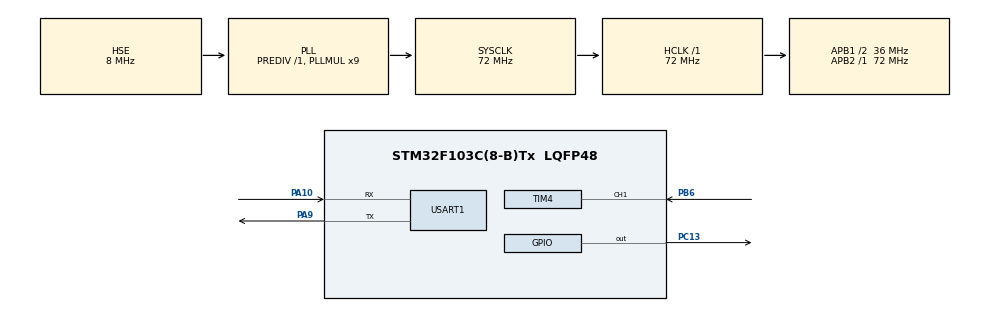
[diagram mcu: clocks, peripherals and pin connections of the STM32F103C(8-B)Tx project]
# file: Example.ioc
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FREERTOS.Tasks01=logger,0,512,StartLogger,Default,NULL,Dynamic,NULL,NULL
FREERTOS.configMAX_PRIORITIES=5
FREERTOS.configTOTAL_HEAP_SIZE=8192
Mcu.Family=STM32F1
Mcu.Name=STM32F103C(8-B)Tx
Mcu.Package=LQFP48
NVIC.PriorityGroup=NVIC_PRIORITYGROUP_4
NVIC.TIM2_IRQn=true\:15\:0\:false\:false\:true\:false\:false\:true\:true
NVIC.TIM4_IRQn=true\:5\:0\:false\:false\:true\:true\:true\:true\:true
NVIC.TimeBase=TIM2_IRQn
NVIC.TimeBaseIP=TIM2
PA10.Mode=Asynchronous
PA10.Signal=USART1_RX
PA9.Mode=Asynchronous
PA9.Signal=USART1_TX
PB6.Signal=S_TIM4_CH1
PC13-TAMPER-RTC.Signal=GPIO_Output
PD0-OSC_IN.Mode=HSE-External-Oscillator
PD0-OSC_IN.Signal=RCC_OSC_IN
PD1-OSC_OUT.Mode=HSE-External-Oscillator
PD1-OSC_OUT.Signal=RCC_OSC_OUT
ProjectManager.HeapSize=0x200
ProjectManager.StackSize=0x400
ProjectManager.TargetToolchain=Makefile
RCC.AHBFreq_Value=72000000
RCC.APB1CLKDivider=RCC_HCLK_DIV2
RCC.APB1Freq_Value=36000000
RCC.APB1TimFreq_Value=72000000
RCC.APB2Freq_Value=72000000
RCC.APB2TimFreq_Value=72000000
RCC.HCLKFreq_Value=72000000
RCC.PLLMUL=RCC_PLL_MUL9
RCC.PLLSourceVirtual=RCC_PLLSOURCE_HSE
RCC.SYSCLKFreq_VALUE=72000000
RCC.SYSCLKSource=RCC_SYSCLKSOURCE_PLLCLK
RCC.USBFreq_Value=72000000
SH.S_TIM4_CH1.0=TIM4_CH1,Input_Capture1_from_TI1
SH.S_TIM4_CH1.1=TIM4_CH1,TriggerSource_TI1FP1
TIM4.Channel-Input_Capture1_from_TI1=TIM_CHANNEL_1
TIM4.ICFilter_CH1=8
TIM4.Prescaler=71
USART1.VirtualMode=VM_ASYNC
VP_FREERTOS_VS_CMSIS_V1.Mode=CMSIS_V1
VP_SYS_VS_ND.Mode=No_Debug
VP_SYS_VS_tim2.Mode=TIM2
VP_TIM4_VS_ControllerModeReset.Mode=Reset Mode
board=custom

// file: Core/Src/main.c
/* USER CODE BEGIN Header */
/**
  ******************************************************************************
  * @file           : main.c
  * @brief          : Main program body
  ******************************************************************************
  * @attention
  *
  * Copyright (c) 2026 STMicroelectronics.
  * All rights reserved.
  *
  * This software is licensed under terms that can be found in the LICENSE file
  * in the root directory of this software component.
  * If no LICENSE file comes with this software, it is provided AS-IS.
  *
  ******************************************************************************
  */
/* USER CODE END Header */
#include "main.h"
#include "cmsis_os.h"
#include "tim.h"
#include "usart.h"
#include "gpio.h"

/* USER CODE BEGIN PV */
volatile uint32_t diff_ticks = 0;
volatile uint8_t new_read = 0;
/* USER CODE END PV */

void SystemClock_Config(void);
void MX_FREERTOS_Init(void);

int main(void)
{

  /* MCU Configuration--------------------------------------------------------*/

  /* Reset of all peripherals, Initializes the Flash interface and the Systick. */
  HAL_Init();

  /* Configure the system clock */
  SystemClock_Config();

  /* Initialize all configured peripherals */
  MX_GPIO_Init();
  MX_USART1_UART_Init();
  MX_TIM4_Init();
  HAL_TIM_IC_Start_IT(&htim4, TIM_CHANNEL_1);

  /* Call init function for freertos objects (in cmsis_os2.c) */
  MX_FREERTOS_Init();

  /* Start scheduler */
  osKernelStart();

  /* We should never get here as control is now taken by the scheduler */

  /* Infinite loop */
  while (1)
  {

  }
}

void SystemClock_Config(void)
{
  RCC_OscInitTypeDef RCC_OscInitStruct = {0};
  RCC_ClkInitTypeDef RCC_ClkInitStruct = {0};

  /** Initializes the RCC Oscillators according to the specified parameters
  * in the RCC_OscInitTypeDef structure.
  */
  RCC_OscInitStruct.OscillatorType = RCC_OSCILLATORTYPE_HSE;
  RCC_OscInitStruct.HSEState = RCC_HSE_ON;
  RCC_OscInitStruct.HSEPredivValue = RCC_HSE_PREDIV_DIV1;
  RCC_OscInitStruct.HSIState = RCC_HSI_ON;
  RCC_OscInitStruct.PLL.PLLState = RCC_PLL_ON;
  RCC_OscInitStruct.PLL.PLLSource = RCC_PLLSOURCE_HSE;
  RCC_OscInitStruct.PLL.PLLMUL = RCC_PLL_MUL9;
  if (HAL_RCC_OscConfig(&RCC_OscInitStruct) != HAL_OK)
  {
    Error_Handler();
  }

  /** Initializes the CPU, AHB and APB buses clocks
  */
  RCC_ClkInitStruct.ClockType = RCC_CLOCKTYPE_HCLK|RCC_CLOCKTYPE_SYSCLK
                              |RCC_CLOCKTYPE_PCLK1|RCC_CLOCKTYPE_PCLK2;
  RCC_ClkInitStruct.SYSCLKSource = RCC_SYSCLKSOURCE_PLLCLK;
  RCC_ClkInitStruct.AHBCLKDivider = RCC_SYSCLK_DIV1;
  RCC_ClkInitStruct.APB1CLKDivider = RCC_HCLK_DIV2;
  RCC_ClkInitStruct.APB2CLKDivider = RCC_HCLK_DIV1;

  if (HAL_RCC_ClockConfig(&RCC_ClkInitStruct, FLASH_LATENCY_2) != HAL_OK)
  {
    Error_Handler();
  }
}

/* USER CODE BEGIN 4 */
void HAL_TIM_IC_CaptureCallback(TIM_HandleTypeDef *htim)
{
    if (htim->Instance == TIM4)
    {
        diff_ticks = HAL_TIM_ReadCapturedValue(htim, TIM_CHANNEL_1);
        new_read = 1;
    }
}
/* UART printf support */
int _write(int file, char *ptr, int len)
{
  HAL_UART_Transmit(&huart1, (uint8_t*)ptr, len, HAL_MAX_DELAY);
  return len;
}
/* USER CODE END 4 */

void HAL_TIM_PeriodElapsedCallback(TIM_HandleTypeDef *htim)
{
  if (htim->Instance == TIM2)
  {
    HAL_IncTick();
  }
}

void Error_Handler(void)
{
  __disable_irq();
  while (1)
  {
  }
}

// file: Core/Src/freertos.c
/* USER CODE BEGIN Header */
/**
  ******************************************************************************
  * File Name          : freertos.c
  * Description        : Code for freertos applications
  ******************************************************************************
  * @attention
  *
  * Copyright (c) 2026 STMicroelectronics.
  * All rights reserved.
  *
  * This software is licensed under terms that can be found in the LICENSE file
  * in the root directory of this software component.
  * If no LICENSE file comes with this software, it is provided AS-IS.
  *
  ******************************************************************************
  */
/* USER CODE END Header */

#include "FreeRTOS.h"
#include "task.h"
#include "main.h"
#include "cmsis_os.h"

/* USER CODE BEGIN Variables */
extern volatile uint32_t diff_ticks;
extern volatile uint8_t new_read;
/* USER CODE END Variables */
osThreadId loggerHandle;

void StartLogger(void const * argument);

void MX_FREERTOS_Init(void); /* (MISRA C 2004 rule 8.1) */

/* GetIdleTaskMemory prototype (linked to static allocation support) */
void vApplicationGetIdleTaskMemory( StaticTask_t **ppxIdleTaskTCBBuffer, StackType_t **ppxIdleTaskStackBuffer, uint32_t *pulIdleTaskStackSize );

/* USER CODE BEGIN GET_IDLE_TASK_MEMORY */
static StaticTask_t xIdleTaskTCBBuffer;
static StackType_t xIdleStack[configMINIMAL_STACK_SIZE];

void vApplicationGetIdleTaskMemory( StaticTask_t **ppxIdleTaskTCBBuffer, StackType_t **ppxIdleTaskStackBuffer, uint32_t *pulIdleTaskStackSize )
{
  *ppxIdleTaskTCBBuffer = &xIdleTaskTCBBuffer;
  *ppxIdleTaskStackBuffer = &xIdleStack[0];
  *pulIdleTaskStackSize = configMINIMAL_STACK_SIZE;
  /* place for user code */
}
/* USER CODE END GET_IDLE_TASK_MEMORY */

void MX_FREERTOS_Init(void) {

  /* Create the thread(s) */
  /* definition and creation of logger */
  osThreadDef(logger, StartLogger, osPriorityNormal, 0, 512);
  loggerHandle = osThreadCreate(osThread(logger), NULL);

}

void StartLogger(void const * argument)
{
  /* Variables locales para el cálculo */
  uint32_t acumulador_ticks = 0;
  uint8_t contador_pulsos = 0;
  float rpm_suave = 0.0f;

  for(;;)
  {
    if (new_read)
    {
        taskENTER_CRITICAL();
        uint32_t current_ticks = diff_ticks;
        new_read = 0;
        taskEXIT_CRITICAL();

        // 8 pulsos para promediar la vuelta completa
        acumulador_ticks += current_ticks;
        contador_pulsos++;

        if (contador_pulsos >= 8)
        {
            // 2. Calculamos el promedio de la vuelta
            float promedio_ticks = (float)acumulador_ticks / 8;

            // 3. RPM = 60,000,000 / (promedio * 8)
            // O simplificado: 7,500,000 / promedio
            rpm_suave = 7500000.0f / promedio_ticks;

            // 4. Limpiamos para la siguiente vuelta
            acumulador_ticks = 0;
            contador_pulsos = 0;

            // 5. Imprimir el dato limpio para el modelo de ML
            printf("%.2f\n", rpm_suave);
        }
    }

    // Un delay pequeño para no saturar la CPU
    vTaskDelay(pdMS_TO_TICKS(5));
  }

}
